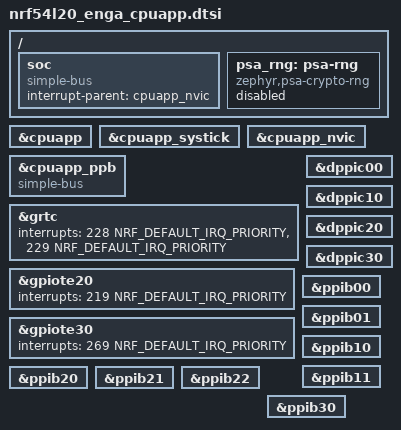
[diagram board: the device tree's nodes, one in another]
/*
 * Copyright (c) 2024 Nordic Semiconductor ASA
 *
 * SPDX-License-Identifier: Apache-2.0
 */

#include <nordic/nrf54l20.dtsi>

cpu: &cpuapp {};
systick: &cpuapp_systick {};
nvic: &cpuapp_nvic {};

/ {
	soc {
		compatible = "simple-bus";
		interrupt-parent = <&cpuapp_nvic>;
		ranges;
	};

	psa_rng: psa-rng {
		compatible = "zephyr,psa-crypto-rng";
		status = "disabled";
	};
};

&cpuapp_ppb {
	compatible = "simple-bus";
	ranges;
};

&grtc {
	interrupts = <228 NRF_DEFAULT_IRQ_PRIORITY>,
		<229 NRF_DEFAULT_IRQ_PRIORITY>; /* reserved for Zero Latency IRQs */
};

&gpiote20 {
	interrupts = <219 NRF_DEFAULT_IRQ_PRIORITY>;
};

&gpiote30 {
	interrupts = <269 NRF_DEFAULT_IRQ_PRIORITY>;
};

&dppic00 {
	status = "okay";
};

&dppic10 {
	status = "okay";
};

&dppic20 {
	status = "okay";
};

&dppic30 {
	status = "okay";
};

&ppib00 {
	status = "okay";
};

&ppib01 {
	status = "okay";
};

&ppib10 {
	status = "okay";
};

&ppib11 {
	status = "okay";
};

&ppib20 {
	status = "okay";
};

&ppib21 {
	status = "okay";
};

&ppib22 {
	status = "okay";
};

&ppib30 {
	status = "okay";
};
